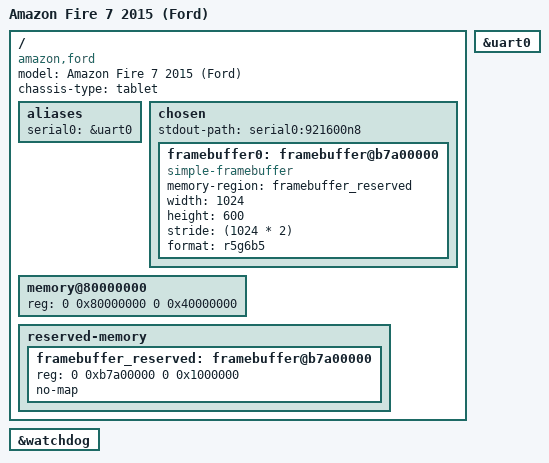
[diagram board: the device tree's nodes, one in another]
// SPDX-License-Identifier: GPL-2.0

/dts-v1/;
#include "mt8127.dtsi"

/ {
	model = "Amazon Fire 7 2015 (Ford)";
	compatible = "amazon,ford", "mediatek,mt8127";
	chassis-type = "tablet";

	aliases {
		serial0 = &uart0;
	};

	chosen {
		#address-cells = <2>;
		#size-cells = <2>;
		ranges;
		stdout-path = "serial0:921600n8";

		framebuffer0: framebuffer@b7a00000 {
			compatible = "simple-framebuffer";
			memory-region = <&framebuffer_reserved>;
			width = <1024>;
			height = <600>;
			stride = <(1024 * 2)>;
			format = "r5g6b5";
		};
	};

	memory@80000000 {
		device_type = "memory";
		reg = <0 0x80000000 0 0x40000000>;
	};

	reserved-memory {
		#address-cells = <2>;
		#size-cells = <2>;
		ranges;

		framebuffer_reserved: framebuffer@b7a00000 {
			reg = <0 0xb7a00000 0 0x1000000>;
			no-map;
		};
	};
};

&uart0 {
	status = "okay";
};

&watchdog {
	status = "okay";
};
